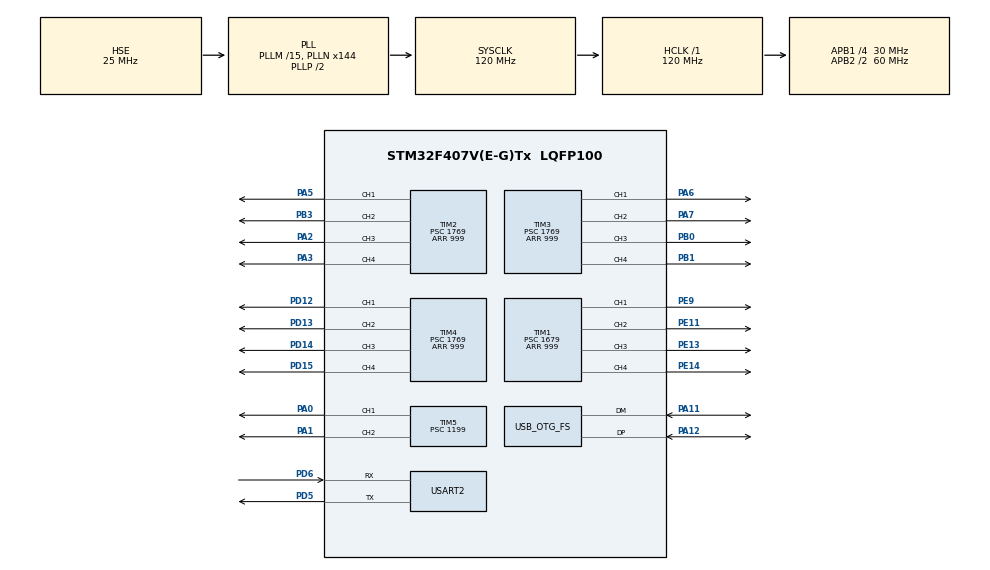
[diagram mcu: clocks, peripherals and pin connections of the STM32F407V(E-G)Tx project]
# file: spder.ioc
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Dma.Request0=USART2_RX
Dma.Request1=USART2_TX
Dma.USART2_RX.0.Direction=DMA_PERIPH_TO_MEMORY
Dma.USART2_RX.0.FIFOMode=DMA_FIFOMODE_DISABLE
Dma.USART2_RX.0.Instance=DMA1_Stream5
Dma.USART2_RX.0.MemDataAlignment=DMA_MDATAALIGN_BYTE
Dma.USART2_RX.0.MemInc=DMA_MINC_ENABLE
Dma.USART2_RX.0.Mode=DMA_NORMAL
Dma.USART2_RX.0.PeriphDataAlignment=DMA_PDATAALIGN_BYTE
Dma.USART2_RX.0.PeriphInc=DMA_PINC_DISABLE
Dma.USART2_RX.0.Priority=DMA_PRIORITY_LOW
Dma.USART2_TX.1.Direction=DMA_MEMORY_TO_PERIPH
Dma.USART2_TX.1.FIFOMode=DMA_FIFOMODE_DISABLE
Dma.USART2_TX.1.Instance=DMA1_Stream6
Dma.USART2_TX.1.MemDataAlignment=DMA_MDATAALIGN_BYTE
Dma.USART2_TX.1.MemInc=DMA_MINC_ENABLE
Dma.USART2_TX.1.Mode=DMA_NORMAL
Dma.USART2_TX.1.PeriphDataAlignment=DMA_PDATAALIGN_BYTE
Dma.USART2_TX.1.PeriphInc=DMA_PINC_DISABLE
Dma.USART2_TX.1.Priority=DMA_PRIORITY_LOW
FREERTOS.Tasks01=defaultTask,24,128,StartDefaultTask,Default,NULL,Dynamic,NULL,NULL
Mcu.Family=STM32F4
Mcu.Name=STM32F407V(E-G)Tx
Mcu.Package=LQFP100
NVIC.DMA1_Stream5_IRQn=true\:5\:0\:false\:false\:true\:true\:false\:true\:true
NVIC.DMA1_Stream6_IRQn=true\:5\:0\:false\:false\:true\:true\:false\:true\:true
NVIC.OTG_FS_IRQn=true\:5\:0\:false\:false\:true\:true\:false\:true\:true
NVIC.PriorityGroup=NVIC_PRIORITYGROUP_4
NVIC.TIM8_TRG_COM_TIM14_IRQn=true\:15\:0\:false\:false\:true\:false\:false\:true\:true
NVIC.TimeBase=TIM8_TRG_COM_TIM14_IRQn
NVIC.TimeBaseIP=TIM14
NVIC.USART2_IRQn=true\:5\:0\:false\:false\:true\:true\:true\:true\:true
PA0-WKUP.Signal=S_TIM5_CH1
PA1.Signal=S_TIM5_CH2
PA11.Mode=Device_Only
PA11.Signal=USB_OTG_FS_DM
PA12.Mode=Device_Only
PA12.Signal=USB_OTG_FS_DP
PA2.Signal=S_TIM2_CH3
PA3.Signal=S_TIM2_CH4
PA5.Signal=S_TIM2_CH1_ETR
PA6.Signal=S_TIM3_CH1
PA7.Signal=S_TIM3_CH2
PB0.Signal=S_TIM3_CH3
PB1.Signal=S_TIM3_CH4
PB3.Signal=S_TIM2_CH2
PD12.Signal=S_TIM4_CH1
PD13.Signal=S_TIM4_CH2
PD14.Signal=S_TIM4_CH3
PD15.Signal=S_TIM4_CH4
PD5.Mode=Asynchronous
PD5.Signal=USART2_TX
PD6.Mode=Asynchronous
PD6.Signal=USART2_RX
PE11.Signal=S_TIM1_CH2
PE13.Signal=S_TIM1_CH3
PE14.Signal=S_TIM1_CH4
PE9.Signal=S_TIM1_CH1
PH0-OSC_IN.Mode=HSE-External-Oscillator
PH0-OSC_IN.Signal=RCC_OSC_IN
PH1-OSC_OUT.Mode=HSE-External-Oscillator
PH1-OSC_OUT.Signal=RCC_OSC_OUT
ProjectManager.HeapSize=0x200
ProjectManager.StackSize=0x400
ProjectManager.TargetToolchain=MDK-ARM V5.32
RCC.48MHZClocksFreq_Value=48000000
RCC.AHBFreq_Value=120000000
RCC.APB1CLKDivider=RCC_HCLK_DIV4
RCC.APB1Freq_Value=30000000
RCC.APB1TimFreq_Value=60000000
RCC.APB2CLKDivider=RCC_HCLK_DIV2
RCC.APB2Freq_Value=60000000
RCC.APB2TimFreq_Value=120000000
RCC.CortexFreq_Value=120000000
RCC.HCLKFreq_Value=120000000
RCC.HSE_VALUE=25000000
RCC.HSI_VALUE=16000000
RCC.LSE_VALUE=32768
RCC.PLLM=15
RCC.PLLN=144
RCC.PLLQ=5
RCC.SYSCLKFreq_VALUE=120000000
RCC.SYSCLKSource=RCC_SYSCLKSOURCE_PLLCLK
RCC.VCOOutputFreq_Value=240000000
SH.S_TIM1_CH1.0=TIM1_CH1,PWM Generation1 CH1
SH.S_TIM1_CH2.0=TIM1_CH2,PWM Generation2 CH2
SH.S_TIM1_CH3.0=TIM1_CH3,PWM Generation3 CH3
SH.S_TIM1_CH4.0=TIM1_CH4,PWM Generation4 CH4
SH.S_TIM2_CH1_ETR.0=TIM2_CH1,PWM Generation1 CH1
SH.S_TIM2_CH2.0=TIM2_CH2,PWM Generation2 CH2
SH.S_TIM2_CH3.0=TIM2_CH3,PWM Generation3 CH3
SH.S_TIM2_CH4.0=TIM2_CH4,Output Compare4 CH4
SH.S_TIM3_CH1.0=TIM3_CH1,PWM Generation1 CH1
SH.S_TIM3_CH2.0=TIM3_CH2,PWM Generation2 CH2
SH.S_TIM3_CH3.0=TIM3_CH3,Forced Output3 CH3
SH.S_TIM3_CH4.0=TIM3_CH4,PWM Generation4 CH4
SH.S_TIM4_CH1.0=TIM4_CH1,PWM Generation1 CH1
SH.S_TIM4_CH2.0=TIM4_CH2,PWM Generation2 CH2
SH.S_TIM4_CH3.0=TIM4_CH3,PWM Generation3 CH3
SH.S_TIM4_CH4.0=TIM4_CH4,PWM Generation4 CH4
SH.S_TIM5_CH1.0=TIM5_CH1,PWM Generation1 CH1
SH.S_TIM5_CH2.0=TIM5_CH2,PWM Generation2 CH2
TIM1.AutoReloadPreload=TIM_AUTORELOAD_PRELOAD_ENABLE
TIM1.Channel-PWM\ Generation1\ CH1=TIM_CHANNEL_1
TIM1.Channel-PWM\ Generation2\ CH2=TIM_CHANNEL_2
TIM1.Channel-PWM\ Generation3\ CH3=TIM_CHANNEL_3
TIM1.Channel-PWM\ Generation4\ CH4=TIM_CHANNEL_4
TIM1.Period=999
TIM1.Prescaler=1679
TIM2.AutoReloadPreload=TIM_AUTORELOAD_PRELOAD_ENABLE
TIM2.Channel-Output\ Compare4\ CH4=TIM_CHANNEL_4
TIM2.Channel-PWM\ Generation1\ CH1=TIM_CHANNEL_1
TIM2.Channel-PWM\ Generation2\ CH2=TIM_CHANNEL_2
TIM2.Channel-PWM\ Generation3\ CH3=TIM_CHANNEL_3
TIM2.Period=999
TIM2.Prescaler=1769
TIM3.AutoReloadPreload=TIM_AUTORELOAD_PRELOAD_ENABLE
TIM3.Channel-Forced\ Output3\ CH3=TIM_CHANNEL_3
TIM3.Channel-PWM\ Generation1\ CH1=TIM_CHANNEL_1
TIM3.Channel-PWM\ Generation2\ CH2=TIM_CHANNEL_2
TIM3.Channel-PWM\ Generation4\ CH4=TIM_CHANNEL_4
TIM3.Period=999
TIM3.Prescaler=1769
TIM4.AutoReloadPreload=TIM_AUTORELOAD_PRELOAD_ENABLE
TIM4.Channel-PWM\ Generation1\ CH1=TIM_CHANNEL_1
TIM4.Channel-PWM\ Generation2\ CH2=TIM_CHANNEL_2
TIM4.Channel-PWM\ Generation3\ CH3=TIM_CHANNEL_3
TIM4.Channel-PWM\ Generation4\ CH4=TIM_CHANNEL_4
TIM4.Period=999
TIM4.Prescaler=1769
TIM5.AutoReloadPreload=TIM_AUTORELOAD_PRELOAD_ENABLE
TIM5.Channel-PWM\ Generation1\ CH1=TIM_CHANNEL_1
TIM5.Channel-PWM\ Generation2\ CH2=TIM_CHANNEL_2
TIM5.Period=999
TIM5.Prescaler=1199
USART2.VirtualMode=VM_ASYNC
USB_DEVICE.CLASS_NAME_FS=CDC
USB_DEVICE.VirtualMode-CDC_FS=Cdc
USB_DEVICE.VirtualModeFS=Cdc_FS
USB_OTG_FS.VirtualMode=Device_Only
VP_FREERTOS_VS_CMSIS_V2.Mode=CMSIS_V2
VP_SYS_VS_tim14.Mode=TIM14
VP_USB_DEVICE_VS_USB_DEVICE_CDC_FS.Mode=CDC_FS
board=custom

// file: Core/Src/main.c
/* USER CODE BEGIN Header */
/**
  ******************************************************************************
  * @file           : main.c
  * @brief          : Main program body
  ******************************************************************************
  * @attention
  *
  * Copyright (c) 2026 STMicroelectronics.
  * All rights reserved.
  *
  * This software is licensed under terms that can be found in the LICENSE file
  * in the root directory of this software component.
  * If no LICENSE file comes with this software, it is provided AS-IS.
  *
  ******************************************************************************
  */
/* USER CODE END Header */
#include "main.h"
#include "cmsis_os.h"
#include "dma.h"
#include "tim.h"
#include "usart.h"
#include "usb_device.h"
#include "gpio.h"

void SystemClock_Config(void);
void MX_FREERTOS_Init(void);

int main(void)
{

  /* MCU Configuration--------------------------------------------------------*/

  /* Reset of all peripherals, Initializes the Flash interface and the Systick. */
  HAL_Init();

  /* Configure the system clock */
  SystemClock_Config();

  /* Initialize all configured peripherals */
  MX_GPIO_Init();
  MX_DMA_Init();
  MX_TIM1_Init();
  MX_TIM2_Init();
  MX_TIM3_Init();
  MX_TIM4_Init();
  MX_TIM5_Init();
  MX_USART2_UART_Init();

  HAL_TIM_PWM_Start(&htim1,
  TIM_CHANNEL_1);
  HAL_TIM_PWM_Start(&htim1,
  TIM_CHANNEL_2);
  HAL_TIM_PWM_Start(&htim1,
  TIM_CHANNEL_3);
  HAL_TIM_PWM_Start(&htim1,
  TIM_CHANNEL_4);
  HAL_TIM_PWM_Start(&htim2,
  TIM_CHANNEL_1);
  HAL_TIM_PWM_Start(&htim2,
  TIM_CHANNEL_2);
  HAL_TIM_PWM_Start(&htim2,
  TIM_CHANNEL_3);
  HAL_TIM_PWM_Start(&htim2,
  TIM_CHANNEL_4);
  HAL_TIM_PWM_Start(&htim3,
  TIM_CHANNEL_1);
  HAL_TIM_PWM_Start(&htim3,
  TIM_CHANNEL_2);
  HAL_TIM_PWM_Start(&htim3,
  TIM_CHANNEL_3);
  HAL_TIM_PWM_Start(&htim3,
  TIM_CHANNEL_4);
  HAL_TIM_PWM_Start(&htim4,
  TIM_CHANNEL_1);
  HAL_TIM_PWM_Start(&htim4,
  TIM_CHANNEL_2);
  HAL_TIM_PWM_Start(&htim4,
  TIM_CHANNEL_3);
  HAL_TIM_PWM_Start(&htim4,
  TIM_CHANNEL_4);
  HAL_TIM_PWM_Start(&htim5,
  TIM_CHANNEL_1);
  HAL_TIM_PWM_Start(&htim5,
  TIM_CHANNEL_2);

  /* Init scheduler */
  osKernelInitialize();  /* Call init function for freertos objects (in cmsis_os2.c) */
  MX_FREERTOS_Init();

  /* Start scheduler */
  osKernelStart();

  /* We should never get here as control is now taken by the scheduler */

  /* Infinite loop */
  while (1)
  {

  }
}

void SystemClock_Config(void)
{
  RCC_OscInitTypeDef RCC_OscInitStruct = {0};
  RCC_ClkInitTypeDef RCC_ClkInitStruct = {0};

  /** Configure the main internal regulator output voltage
  */
  __HAL_RCC_PWR_CLK_ENABLE();
  __HAL_PWR_VOLTAGESCALING_CONFIG(PWR_REGULATOR_VOLTAGE_SCALE1);

  /** Initializes the RCC Oscillators according to the specified parameters
  * in the RCC_OscInitTypeDef structure.
  */
  RCC_OscInitStruct.OscillatorType = RCC_OSCILLATORTYPE_HSE;
  RCC_OscInitStruct.HSEState = RCC_HSE_ON;
  RCC_OscInitStruct.PLL.PLLState = RCC_PLL_ON;
  RCC_OscInitStruct.PLL.PLLSource = RCC_PLLSOURCE_HSE;
  RCC_OscInitStruct.PLL.PLLM = 15;
  RCC_OscInitStruct.PLL.PLLN = 144;
  RCC_OscInitStruct.PLL.PLLP = RCC_PLLP_DIV2;
  RCC_OscInitStruct.PLL.PLLQ = 5;
  if (HAL_RCC_OscConfig(&RCC_OscInitStruct) != HAL_OK)
  {
    Error_Handler();
  }

  /** Initializes the CPU, AHB and APB buses clocks
  */
  RCC_ClkInitStruct.ClockType = RCC_CLOCKTYPE_HCLK|RCC_CLOCKTYPE_SYSCLK
                              |RCC_CLOCKTYPE_PCLK1|RCC_CLOCKTYPE_PCLK2;
  RCC_ClkInitStruct.SYSCLKSource = RCC_SYSCLKSOURCE_PLLCLK;
  RCC_ClkInitStruct.AHBCLKDivider = RCC_SYSCLK_DIV1;
  RCC_ClkInitStruct.APB1CLKDivider = RCC_HCLK_DIV4;
  RCC_ClkInitStruct.APB2CLKDivider = RCC_HCLK_DIV2;

  if (HAL_RCC_ClockConfig(&RCC_ClkInitStruct, FLASH_LATENCY_3) != HAL_OK)
  {
    Error_Handler();
  }
}

void HAL_TIM_PeriodElapsedCallback(TIM_HandleTypeDef *htim)
{
  if (htim->Instance == TIM14)
  {
    HAL_IncTick();
  }
}

void Error_Handler(void)
{
  __disable_irq();
  while (1)
  {
  }
}

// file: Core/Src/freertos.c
/* USER CODE BEGIN Header */
/**
  ******************************************************************************
  * File Name          : freertos.c
  * Description        : Code for freertos applications
  ******************************************************************************
  * @attention
  *
  * Copyright (c) 2026 STMicroelectronics.
  * All rights reserved.
  *
  * This software is licensed under terms that can be found in the LICENSE file
  * in the root directory of this software component.
  * If no LICENSE file comes with this software, it is provided AS-IS.
  *
  ******************************************************************************
  */
/* USER CODE END Header */

#include "FreeRTOS.h"
#include "task.h"
#include "main.h"
#include "cmsis_os.h"

/* USER CODE BEGIN Includes */
#include "app.h"
/* USER CODE END Includes */

/* Definitions for defaultTask */
osThreadId_t defaultTaskHandle;
const osThreadAttr_t defaultTask_attributes = {
  .name = "defaultTask",
  .stack_size = 128 * 4,
  .priority = (osPriority_t) osPriorityNormal,
};

void StartDefaultTask(void *argument);

extern void MX_USB_DEVICE_Init(void);
void MX_FREERTOS_Init(void); /* (MISRA C 2004 rule 8.1) */

void MX_FREERTOS_Init(void) {

  /* Create the thread(s) */
  /* creation of defaultTask */
  defaultTaskHandle = osThreadNew(StartDefaultTask, NULL, &defaultTask_attributes);

}

void StartDefaultTask(void *argument)
{
  /* init code for USB_DEVICE */
  MX_USB_DEVICE_Init();
  /* USER CODE BEGIN StartDefaultTask */
	Task_Init();
	vTaskDelete(NULL);
  /* Infinite loop */
  for(;;)
  {
    osDelay(1);
  }
  /* USER CODE END StartDefaultTask */
}
